# MK81F25615 register map
Vendor: Freescale Semiconductor, Inc.; Series: Kinetis_K; File version: 1.6
CPU: CM4 r0p1, little endian, no MPU, FPU, VTOR, 4 interrupt priority bits
Registers are 32-bit, read-write, reset 0x0 unless marked. A register's access mark holds for its fields unless they carry their own. Offsets are from the block's base; [hi:lo] are bit positions; {n}, {i} and the like mark numbered series; 'fields as' and 'values as' point back to an identical list.

## SDRAM — Synchronous DRAM Controller
Base 0x4000F000; register names take the prefix SDRAM_
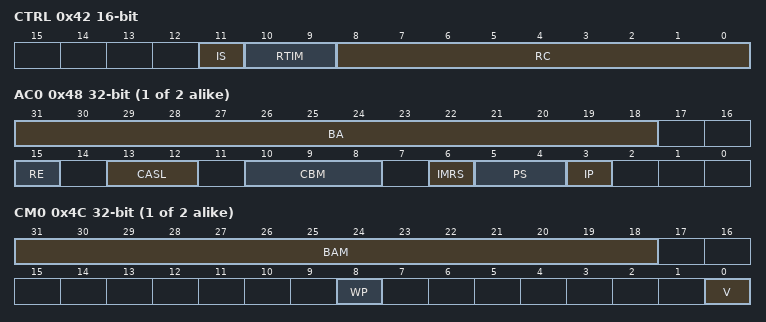
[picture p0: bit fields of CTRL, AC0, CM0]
0x42 CTRL 16-bit reset not defined — Control Register
  [11] IS — Initiate self-refresh command.
    0=Take no action or issue a selfx command to exit self refresh; 1=SDRAM controller sends a self command to both SDRAM blocks to put them in low-power, self-refresh state where they remain until IS is cleared. When IS is cleared, the controller sends a selfx command for the SDRAMs to exit self-refresh. The refresh counter is suspended while the SDRAMs are in self-refresh; the SDRAM controls the refresh period.
  [10:9] RTIM — Refresh timing
    0=3 clocks; 1=6 clocks; 2=9 clocks; 3=9 clocks
  [8:0] RC — Refresh count
{0x48+8i} AC{i} (i=0..1) (reset mask 0x8040) — Address and Control Register
  [31:18] BA — Base address register.
  [15] RE — Refresh enable
    0=Do not refresh associated DRAM block; 1=Refresh associated DRAM block
  [13:12] CASL — CAS Latency
  [10:8] CBM — Command bit location
  [6] IMRS — Initiate mode register set (mrs) command.
    0=Take no action; 1=Initiate mrs command
  [5:4] PS — Port size.
    0=32-bit port; 1=8-bit port; 2=16-bit port; 3=16-bit port
  [3] IP — Initiate precharge all (pall) command.
    0=Take no action; 1=A pall command is sent to the associated SDRAM block. During initialization, this command is executed after all DRAM controller registers are programmed. After IP is set, the next write to an appropriate SDRAM address generates the pall command to the SDRAM block.
{0x4C+8i} CM{i} (i=0..1) (reset mask 0x1) — Control Mask
  [31:18] BAM — Base address mask.
    0=The associated address bit is used in decoding the DRAM hit to a memory block; 1=The associated address bit is not used in the DRAM hit decode
  [8] WP — Write protect.
    0=Allow write accesses; 1=Ignore write accesses. The DRAM controller ignores write accesses to the memory block and an address exception occurs. Write accesses to a write-protected DRAM region are compared in the chip select module for a hit. If no hit occurs, an external bus cycle is generated. If this external bus cycle is not acknowledged, an access exception occurs.
  [0] V — Valid.
    0=Do not decode DRAM accesses; 1=Registers controlling the DRAM block are initialized; DRAM accesses can be decoded

## DMAMUX — DMA channel multiplexor
Base 0x40021000; register names take the prefix DMAMUX_
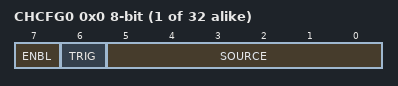
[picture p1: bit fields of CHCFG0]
{0x0+i} CHCFG{i} (i=0..31) 8-bit — Channel Configuration register
  [7] ENBL — DMA Channel Enable
    0=DMA channel is disabled. This mode is primarily used during configuration of the DMAMux. The DMA has separate channel enables/disables, which should be used to disable or reconfigure a DMA channel.; 1=DMA channel is enabled
  [6] TRIG — DMA Channel Trigger Enable
    0=Triggering is disabled. If triggering is disabled and ENBL is set, the DMA Channel will simply route the specified source to the DMA channel. (Normal mode); 1=Triggering is enabled. If triggering is enabled and ENBL is set, the DMAMUX is in Periodic Trigger mode.
  [5:0] SOURCE — DMA Channel Source (Slot)

## CRC — Cyclic Redundancy Check
Base 0x40032000; register names take the prefix CRC_
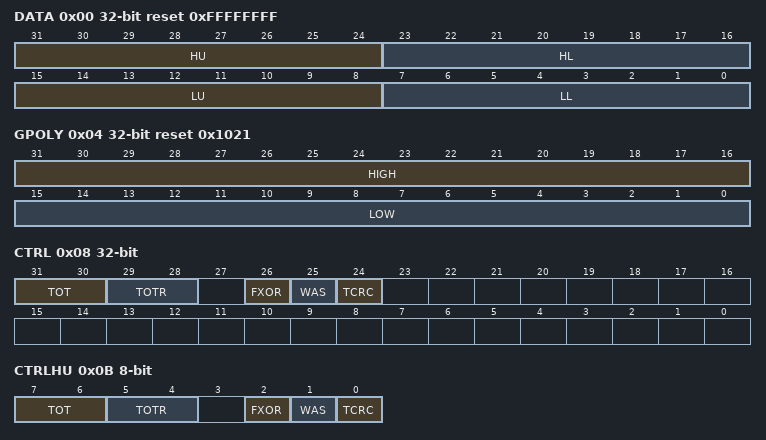
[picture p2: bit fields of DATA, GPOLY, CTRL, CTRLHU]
0x00 DATA reset 0xFFFFFFFF (CRC view) — CRC Data register
  [31:24] HU — CRC High Upper Byte
  [23:16] HL — CRC High Lower Byte
  [15:8] LU — CRC Low Upper Byte
  [7:0] LL — CRC Low Lower Byte
0x00 DATAL 16-bit reset 0xFFFF (CRC view) — CRC_DATAL register.
  [15:0] DATAL — DATAL stores the lower 16 bits of the 16/32 bit CRC
0x00 DATALL 8-bit reset 0xFF (CRC view) — CRC_DATALL register.
  [7:0] DATALL — CRCLL stores the first 8 bits of the 32 bit DATA
0x01 DATALU 8-bit reset 0xFF — CRC_DATALU register.
  [7:0] DATALU — DATALL stores the second 8 bits of the 32 bit CRC
0x02 DATAH 16-bit reset 0xFFFF (CRC view) — CRC_DATAH register.
  [15:0] DATAH — DATAH stores the high 16 bits of the 16/32 bit CRC
0x02 DATAHL 8-bit reset 0xFF (CRC view) — CRC_DATAHL register.
  [7:0] DATAHL — DATAHL stores the third 8 bits of the 32 bit CRC
0x03 DATAHU 8-bit reset 0xFF — CRC_DATAHU register.
  [7:0] DATAHU — DATAHU stores the fourth 8 bits of the 32 bit CRC
0x04 GPOLY reset 0x1021 (CRC view) — CRC Polynomial register
  [31:16] HIGH — High Polynominal Half-word
  [15:0] LOW — Low Polynominal Half-word
0x04 GPOLYL 16-bit reset 0xFFFF (CRC view) — CRC_GPOLYL register.
  [15:0] GPOLYL — POLYL stores the lower 16 bits of the 16/32 bit CRC polynomial value
0x04 GPOLYLL 8-bit reset 0xFF (CRC view) — CRC_GPOLYLL register.
  [7:0] GPOLYLL — POLYLL stores the first 8 bits of the 32 bit CRC
0x05 GPOLYLU 8-bit reset 0xFF — CRC_GPOLYLU register.
  [7:0] GPOLYLU — POLYLL stores the second 8 bits of the 32 bit CRC
0x06 GPOLYH 16-bit reset 0xFFFF (CRC view) — CRC_GPOLYH register.
  [15:0] GPOLYH — POLYH stores the high 16 bits of the 16/32 bit CRC polynomial value
0x06 GPOLYHL 8-bit reset 0xFF (CRC view) — CRC_GPOLYHL register.
  [7:0] GPOLYHL — POLYHL stores the third 8 bits of the 32 bit CRC
0x07 GPOLYHU 8-bit reset 0xFF — CRC_GPOLYHU register.
  [7:0] GPOLYHU — POLYHU stores the fourth 8 bits of the 32 bit CRC
0x08 CTRL — CRC Control register
  [31:30] TOT — Type Of Transpose For Writes
    0=No transposition; 1=Bits in bytes are transposed; bytes are not transposed; 2=Both bits in bytes and bytes are transposed; 3=Only bytes are transposed; no bits in a byte are transposed
  [29:28] TOTR — Type Of Transpose For Read
    values as TOT
  [26] FXOR — Complement Read Of CRC Data Register
    0=No XOR on reading; 1=Invert or complement the read value of the CRC Data register
  [25] WAS — Write CRC Data Register As Seed
    0=Writes to the CRC data register are data values; 1=Writes to the CRC data register are seed values
  [24] TCRC — Width of CRC protocol.
    0=16-bit CRC protocol; 1=32-bit CRC protocol
0x0B CTRLHU 8-bit — CRC_CTRLHU register.
  [7:6] TOT
    0=No Transposition; 1=Bits in bytes are transposed, bytes are not transposed; 2=Both bits in bytes and bytes are transposed; 3=Only bytes are transposed; no bits in a byte are transposed
  [5:4] TOTR
    values as TOT
  [2] FXOR
    0=No XOR on reading; 1=Invert or complement the read value of CRC data register
  [1] WAS
    0=Writes to CRC data register are data values; 1=Writes to CRC data reguster are seed values
  [0] TCRC
    0=16-bit CRC protocol; 1=32-bit CRC protocol
